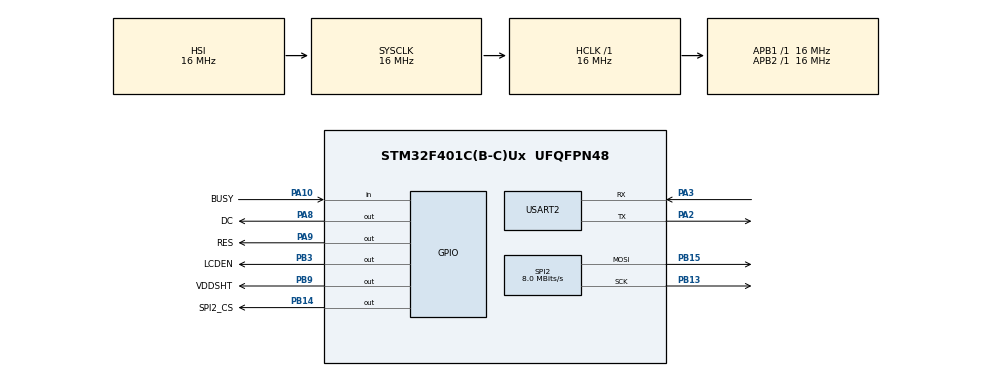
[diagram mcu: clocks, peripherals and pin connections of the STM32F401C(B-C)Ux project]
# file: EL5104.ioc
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Mcu.Family=STM32F4
Mcu.Name=STM32F401C(B-C)Ux
Mcu.Package=UFQFPN48
NVIC.PriorityGroup=NVIC_PRIORITYGROUP_4
NVIC.USART2_IRQn=true\:7\:0\:true\:false\:true\:true\:true
PA10.GPIO_Label=BUSY
PA10.GPIO_PuPd=GPIO_PULLUP
PA10.Signal=GPIO_Input
PA13.Mode=Serial_Wire
PA13.Signal=SYS_JTMS-SWDIO
PA14.Mode=Serial_Wire
PA14.Signal=SYS_JTCK-SWCLK
PA2.Mode=Asynchronous
PA2.Signal=USART2_TX
PA3.Mode=Asynchronous
PA3.Signal=USART2_RX
PA8.GPIO_Label=DC
PA8.Signal=GPIO_Output
PA9.GPIO_Label=RES
PA9.Signal=GPIO_Output
PB13.Mode=TX_Only_Simplex_Unidirect_Master
PB13.Signal=SPI2_SCK
PB14.GPIO_Label=SPI2_CS
PB14.Signal=GPIO_Output
PB15.Mode=TX_Only_Simplex_Unidirect_Master
PB15.Signal=SPI2_MOSI
PB3.GPIO_Label=LCDEN
PB3.GPIO_ModeDefaultOutputPP=GPIO_MODE_OUTPUT_PP
PB3.GPIO_PuPd=GPIO_NOPULL
PB3.PinState=GPIO_PIN_SET
PB3.Signal=GPIO_Output
PB6.Signal=I2C1_SCL
PB7.Signal=I2C1_SDA
PB9.GPIO_Label=VDDSHT
PB9.PinState=GPIO_PIN_SET
PB9.Signal=GPIO_Output
PC14-OSC32_IN.Mode=LSE-External-Oscillator
PC14-OSC32_IN.Signal=RCC_OSC32_IN
PC15-OSC32_OUT.Mode=LSE-External-Oscillator
PC15-OSC32_OUT.Signal=RCC_OSC32_OUT
ProjectManager.HeapSize=0x200
ProjectManager.StackSize=0x400
ProjectManager.TargetToolchain=MDK-ARM V5.27
RCC.AHBFreq_Value=16000000
RCC.APB1Freq_Value=16000000
RCC.APB2Freq_Value=16000000
RCC.CortexFreq_Value=16000000
RCC.HSE_VALUE=25000000
RCC.HSI_VALUE=16000000
RCC.SYSCLKFreq_VALUE=16000000
RCC.VCOOutputFreq_Value=192000000
SPI2.CalculateBaudRate=8.0 MBits/s
SPI2.Direction=SPI_DIRECTION_2LINES
SPI2.Mode=SPI_MODE_MASTER
SPI2.VirtualType=VM_MASTER
USART2.VirtualMode=VM_ASYNC
VP_RTC_VS_RTC_Activate.Mode=RTC_Enabled
VP_RTC_VS_RTC_Calendar.Mode=RTC_Calendar
board=custom

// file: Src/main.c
/* USER CODE BEGIN Header */
/**
  ******************************************************************************
  * @file           : main.c
  * @brief          : Main program body
  ******************************************************************************
  * @attention
  *
  * <h2><center>&copy; Copyright (c) 2020 STMicroelectronics.
  * All rights reserved.</center></h2>
  *
  * This software component is licensed by ST under BSD 3-Clause license,
  * the "License"; You may not use this file except in compliance with the
  * License. You may obtain a copy of the License at:
  *                        opensource.org/licenses/BSD-3-Clause
  *
  ******************************************************************************
  */
/* USER CODE END Header */

#include "main.h"
#include "rtc.h"
#include "spi.h"
#include "usart.h"
#include "gpio.h"

/* USER CODE BEGIN Includes */
#include "lcddrv.h"
#include "pic.h"
/* USER CODE END Includes */

void SystemClock_Config(void);

int main(void)
{

  /* MCU Configuration--------------------------------------------------------*/

  /* Reset of all peripherals, Initializes the Flash interface and the Systick. */
  HAL_Init();

  /* Configure the system clock */
  SystemClock_Config();

  /* Initialize all configured peripherals */
  MX_GPIO_Init();
  MX_RTC_Init();
  MX_SPI2_Init();
  MX_USART2_UART_Init();
  /* USER CODE BEGIN 2 */
  HAL_GPIO_WritePin(GPIOB, LCDEN_Pin, GPIO_PIN_RESET);
  /* USER CODE END 2 */

  /* Infinite loop */
  /* USER CODE BEGIN WHILE */
	EPD_init(); //EPD init
	PIC_clean();
	EPD_refresh();
  PIC_display_Gs();
	EPD_sleep();//EPD_sleep,Sleep instruction is necessary, please do not delete!!!
	HAL_Delay(80);
  while (1)
  {

		//EPD_Clean
//		EPD_init(); //EPD init
//	  PIC_display_Clean();//EPD_Clean
//		EPD_refresh();//EPD_refresh
//		EPD_sleep();//EPD_sleep,Sleep instruction is necessary, please do not delete!!!
//		HAL_Delay(80);
    /* USER CODE END WHILE */

  }
}

void SystemClock_Config(void)
{
  RCC_OscInitTypeDef RCC_OscInitStruct = {0};
  RCC_ClkInitTypeDef RCC_ClkInitStruct = {0};
  RCC_PeriphCLKInitTypeDef PeriphClkInitStruct = {0};

  /** Configure the main internal regulator output voltage
  */
  __HAL_RCC_PWR_CLK_ENABLE();
  __HAL_PWR_VOLTAGESCALING_CONFIG(PWR_REGULATOR_VOLTAGE_SCALE2);
  /** Initializes the CPU, AHB and APB busses clocks
  */
  RCC_OscInitStruct.OscillatorType = RCC_OSCILLATORTYPE_HSI|RCC_OSCILLATORTYPE_LSI;
  RCC_OscInitStruct.HSIState = RCC_HSI_ON;
  RCC_OscInitStruct.HSICalibrationValue = RCC_HSICALIBRATION_DEFAULT;
  RCC_OscInitStruct.LSIState = RCC_LSI_ON;
  RCC_OscInitStruct.PLL.PLLState = RCC_PLL_NONE;
  if (HAL_RCC_OscConfig(&RCC_OscInitStruct) != HAL_OK)
  {
    Error_Handler();
  }
  /** Initializes the CPU, AHB and APB busses clocks
  */
  RCC_ClkInitStruct.ClockType = RCC_CLOCKTYPE_HCLK|RCC_CLOCKTYPE_SYSCLK
                              |RCC_CLOCKTYPE_PCLK1|RCC_CLOCKTYPE_PCLK2;
  RCC_ClkInitStruct.SYSCLKSource = RCC_SYSCLKSOURCE_HSI;
  RCC_ClkInitStruct.AHBCLKDivider = RCC_SYSCLK_DIV1;
  RCC_ClkInitStruct.APB1CLKDivider = RCC_HCLK_DIV1;
  RCC_ClkInitStruct.APB2CLKDivider = RCC_HCLK_DIV1;

  if (HAL_RCC_ClockConfig(&RCC_ClkInitStruct, FLASH_LATENCY_0) != HAL_OK)
  {
    Error_Handler();
  }
  PeriphClkInitStruct.PeriphClockSelection = RCC_PERIPHCLK_RTC;
  PeriphClkInitStruct.RTCClockSelection = RCC_RTCCLKSOURCE_LSI;
  if (HAL_RCCEx_PeriphCLKConfig(&PeriphClkInitStruct) != HAL_OK)
  {
    Error_Handler();
  }
}

void Error_Handler(void)
{
}

/************************ (C) COPYRIGHT STMicroelectronics *****END OF FILE****/
